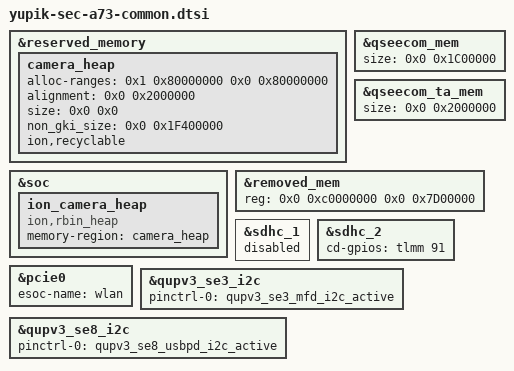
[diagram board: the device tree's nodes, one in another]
/* Copyright (c) 2021, The Linux Foundation. All rights reserved.
 *
 * This program is free software; you can redistribute it and/or modify
 * it under the terms of the GNU General Public License version 2 and
 * only version 2 as published by the Free Software Foundation.
 *
 * This program is distributed in the hope that it will be useful,
 * but WITHOUT ANY WARRANTY; without even the implied warranty of
 * MERCHANTABILITY or FITNESS FOR A PARTICULAR PURPOSE.  See the
 * GNU General Public License for more details.
 */

&reserved_memory {
	camera_heap: camera_heap {
		alloc-ranges = <0x1 0x80000000 0x0 0x80000000>;
		alignment = <0x0 0x2000000>;
		size = <0x0 0x0>;
		non_gki_size = <0x0 0x1F400000>;
		ion,recyclable;
	};
};

&soc {
	ion_camera_heap {
		compatible = "ion,rbin_heap";
		memory-region = <&camera_heap>;
	};
};

&qseecom_mem {
	size = <0x0 0x1C00000>;
};
&qseecom_ta_mem {
	size = <0x0 0x2000000>;
};

&removed_mem {
	reg = <0x0 0xc0000000 0x0 0x7D00000>;
};

&sdhc_1 {                                                                        
	status = "disabled";                                                     
};

&sdhc_2 {
	cd-gpios = <&tlmm 91 GPIO_ACTIVE_HIGH>;
};

&pcie0 {
	esoc-name = "wlan";
};

&qupv3_se3_i2c {
	pinctrl-0 = <&qupv3_se3_mfd_i2c_active>;
	status = "okay";
};

&qupv3_se8_i2c {
	pinctrl-0 = <&qupv3_se8_usbpd_i2c_active>;
	status = "okay";
};
